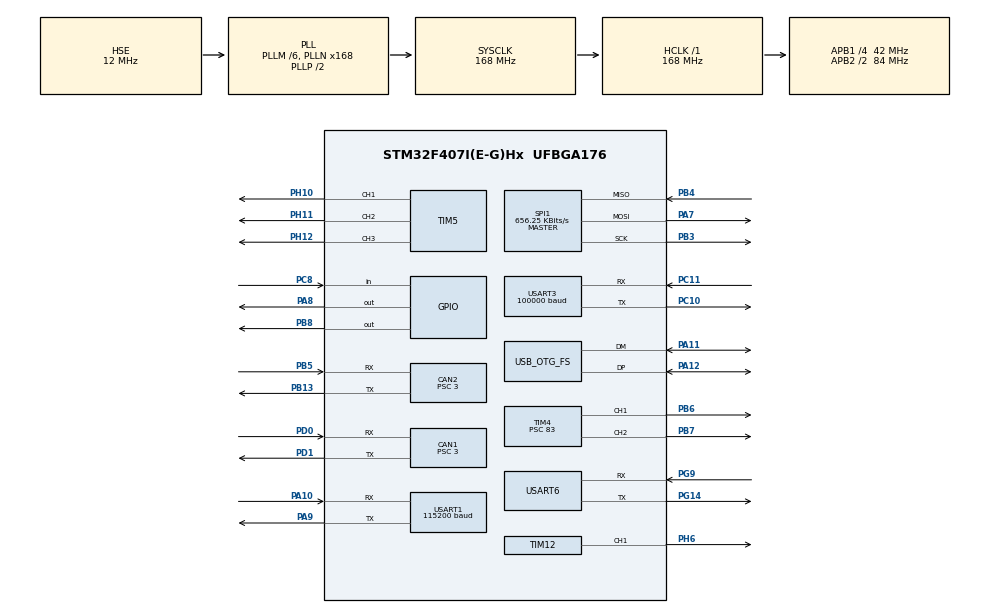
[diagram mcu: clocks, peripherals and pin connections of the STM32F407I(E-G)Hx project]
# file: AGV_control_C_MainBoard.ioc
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Mcu.Family=STM32F4
NVIC.USART3_IRQn=true\:5\:0\:false\:false\:true\:true\:true\:true
Dma.USART6_TX.3.MemInc=DMA_MINC_ENABLE
USB_DEVICE.CLASS_NAME_FS=CDC
PH0-OSC_IN.Signal=RCC_OSC_IN
Dma.USART3_RX.1.Mode=DMA_NORMAL
RCC.CortexFreq_Value=168000000
Dma.USART6_TX.3.PeriphInc=DMA_PINC_DISABLE
PH12.Signal=S_TIM5_CH3
NVIC.CAN2_RX0_IRQn=true\:5\:0\:false\:false\:true\:true\:true\:true
SPI1.VirtualType=VM_MASTER
PH10.Signal=S_TIM5_CH1
CAN1.AWUM=DISABLE
CAN2.CalculateTimeBit=999.99
USART1.BaudRate=115200
Dma.USART6_RX.2.Direction=DMA_PERIPH_TO_MEMORY
PC10.Signal=USART3_TX
SH.S_TIM5_CH2.0=TIM5_CH2,PWM Generation2 CH2
VP_RTC_VS_RTC_Activate.Mode=RTC_Enabled
PA11.Mode=Device_Only
Dma.SPI1_RX.4.PeriphInc=DMA_PINC_DISABLE
USB_DEVICE.VirtualMode-CDC_FS=Cdc
PB13.Signal=CAN2_TX
Dma.USART6_RX.2.MemDataAlignment=DMA_MDATAALIGN_BYTE
RCC.SYSCLKSource=RCC_SYSCLKSOURCE_PLLCLK
ProjectManager.StackSize=0x2000
VP_FREERTOS_VS_CMSIS_V2.Mode=CMSIS_V2
Dma.SPI1_TX.5.Instance=DMA2_Stream3
Dma.USART6_TX.3.PeriphDataAlignment=DMA_PDATAALIGN_BYTE
Dma.USART1_TX.0.Priority=DMA_PRIORITY_MEDIUM
PA12.Signal=USB_OTG_FS_DP
RTC.SynchPrediv=3199
Dma.USART3_RX.1.MemInc=DMA_MINC_ENABLE
USART3.BaudRate=100000
Dma.USART1_TX.0.Direction=DMA_MEMORY_TO_PERIPH
Dma.USART3_RX.1.Instance=DMA1_Stream1
Dma.USART6_TX.3.Priority=DMA_PRIORITY_MEDIUM
NVIC.CAN1_TX_IRQn=true\:5\:0\:false\:false\:true\:true\:true\:true
SPI1.Direction=SPI_DIRECTION_2LINES
RCC.HCLKFreq_Value=168000000
RCC.APB2TimFreq_Value=168000000
PB6.Signal=S_TIM4_CH1
Dma.USART3_RX.1.PeriphDataAlignment=DMA_PDATAALIGN_BYTE
SH.S_TIM5_CH3.0=TIM5_CH3,PWM Generation3 CH3
SPI1.CalculateBaudRate=656.25 KBits/s
Dma.USART6_RX.2.Instance=DMA2_Stream1
PD0.Signal=CAN1_RX
Dma.SPI1_RX.4.MemDataAlignment=DMA_MDATAALIGN_BYTE
RCC.AHBFreq_Value=168000000
PH0-OSC_IN.Mode=HSE-External-Oscillator
RCC.HSE_VALUE=12000000
PB3.Mode=Full_Duplex_Master
TIM12.Period=31111
PG14.Mode=Asynchronous
Dma.USART6_RX.2.Priority=DMA_PRIORITY_HIGH
PB4.Mode=Full_Duplex_Master
SH.S_TIM12_CH1.0=TIM12_CH1,PWM Generation1 CH1
Dma.USART3_RX.1.Priority=DMA_PRIORITY_HIGH
PA14.Mode=Serial_Wire
CAN2.Prescaler=3
PB5.Mode=CAN_Activate
RTC.AsynchPrediv=124
SH.S_TIM4_CH2.0=TIM4_CH2,PWM Generation2 CH2
PB7.Signal=S_TIM4_CH2
Dma.SPI1_TX.5.FIFOMode=DMA_FIFOMODE_DISABLE
PA8.Signal=GPIO_Output
VP_TIM12_VS_ClockSourceINT.Mode=Internal
Dma.SPI1_TX.5.Priority=DMA_PRIORITY_HIGH
TIM4.Period=19999
Dma.USART1_TX.0.PeriphDataAlignment=DMA_PDATAALIGN_BYTE
Dma.SPI1_RX.4.FIFOMode=DMA_FIFOMODE_DISABLE
PH1-OSC_OUT.Mode=HSE-External-Oscillator
Dma.SPI1_RX.4.MemInc=DMA_MINC_ENABLE
CAN1.Prescaler=3
Mcu.Package=UFBGA176
Dma.USART3_RX.1.FIFOMode=DMA_FIFOMODE_DISABLE
NVIC.DMA2_Stream7_IRQn=true\:5\:0\:false\:false\:true\:true\:false\:true
NVIC.TimeBase=TIM3_IRQn
CAN2.BS1=CAN_BS1_10TQ
CAN2.BS2=CAN_BS2_3TQ
USART6.VirtualMode=VM_ASYNC
Dma.USART3_RX.1.Direction=DMA_PERIPH_TO_MEMORY
NVIC.OTG_FS_IRQn=true\:5\:0\:false\:false\:true\:true\:false\:true
NVIC.TimeBaseIP=TIM3
PA10.Signal=USART1_RX
USB_OTG_FS.VirtualMode=Device_Only
Dma.USART1_TX.0.Instance=DMA2_Stream7
Dma.USART1_TX.0.FIFOMode=DMA_FIFOMODE_DISABLE
PC11.Mode=Asynchronous
RCC.APB2CLKDivider=RCC_HCLK_DIV2
Dma.SPI1_TX.5.Direction=DMA_MEMORY_TO_PERIPH
NVIC.DMA2_Stream2_IRQn=true\:5\:0\:false\:false\:true\:true\:false\:true
Dma.USART6_TX.3.MemDataAlignment=DMA_MDATAALIGN_BYTE
SH.S_TIM4_CH1.0=TIM4_CH1,PWM Generation1 CH1
Dma.Request2=USART6_RX
Dma.Request1=USART3_RX
RCC.APB1TimFreq_Value=84000000
Dma.Request4=SPI1_RX
Dma.Request3=USART6_TX
SH.S_TIM5_CH1.0=TIM5_CH1,PWM Generation1 CH1
Dma.Request5=SPI1_TX
PB13.Mode=CAN_Activate
NVIC.USART1_IRQn=true\:5\:0\:false\:false\:true\:true\:true\:true
Dma.Request0=USART1_TX
SPI1.BaudRatePrescaler=SPI_BAUDRATEPRESCALER_128
CAN1.CalculateTimeBit=999.99
PB4.Signal=SPI1_MISO
CAN1.CalculateTimeQuantum=71.42857142857143
Dma.SPI1_TX.5.MemInc=DMA_MINC_ENABLE
TIM4.Channel-PWM\ Generation1\ CH1=TIM_CHANNEL_1
CAN2.CalculateBaudRate=1000000
NVIC.CAN2_TX_IRQn=true\:5\:0\:false\:false\:true\:true\:true\:true
FREERTOS.Tasks01=ChassisTask,24,512,chassis_task,As weak,NULL,Dynamic,NULL,NULL;IMUTask,48,1024,INS_task1,As weak,NULL,Dynamic,NULL,NULL
Dma.USART1_TX.0.MemInc=DMA_MINC_ENABLE
PA7.Mode=Full_Duplex_Master
Dma.SPI1_TX.5.MemDataAlignment=DMA_MDATAALIGN_BYTE
Dma.USART1_TX.0.PeriphInc=DMA_PINC_DISABLE
PA10.Mode=Asynchronous
PH11.Signal=S_TIM5_CH2
USB_DEVICE.VirtualModeFS=Cdc_FS
PG9.Signal=USART6_RX
PC11.Signal=USART3_RX
CAN1.CalculateBaudRate=1000000
PC8.Signal=GPIO_Input
PG9.Mode=Asynchronous
PC10.Mode=Asynchronous
PD1.Signal=CAN1_TX
Dma.USART3_RX.1.MemDataAlignment=DMA_MDATAALIGN_BYTE
TIM5.Channel-PWM\ Generation3\ CH3=TIM_CHANNEL_3
NVIC.DMA1_Stream1_IRQn=true\:5\:0\:false\:false\:true\:true\:false\:true
NVIC.DMA2_Stream1_IRQn=true\:5\:0\:false\:false\:true\:false\:false\:true
RCC.APB1CLKDivider=RCC_HCLK_DIV4
Dma.SPI1_RX.4.Instance=DMA2_Stream2
Dma.USART6_TX.3.Mode=DMA_NORMAL
NVIC.USART6_IRQn=true\:5\:0\:false\:false\:true\:true\:true\:true
PA13.Signal=SYS_JTMS-SWDIO
Dma.SPI1_RX.4.Mode=DMA_NORMAL
PA9.Mode=Asynchronous
VP_SYS_VS_tim3.Mode=TIM3
CAN1.BS2=CAN_BS2_3TQ
CAN1.BS1=CAN_BS1_10TQ
ProjectManager.TargetToolchain=STM32CubeIDE
Dma.USART6_RX.2.MemInc=DMA_MINC_ENABLE
VP_USB_DEVICE_VS_USB_DEVICE_CDC_FS.Mode=CDC_FS
PA9.Signal=USART1_TX
Dma.SPI1_TX.5.Mode=DMA_NORMAL
Dma.USART6_RX.2.PeriphDataAlignment=DMA_PDATAALIGN_BYTE
NVIC.DMA2_Stream3_IRQn=true\:5\:0\:false\:false\:true\:true\:false\:true
NVIC.DMA2_Stream6_IRQn=true\:5\:0\:false\:false\:true\:true\:false\:true
TIM4.Prescaler=83
RCC.LSE_VALUE=32768
CAN1.ABOM=ENABLE
TIM12.Prescaler=1281
PG14.Signal=USART6_TX
Dma.USART6_TX.3.Direction=DMA_MEMORY_TO_PERIPH
Dma.USART1_TX.0.Mode=DMA_NORMAL
board=custom
RCC.VCOOutputFreq_Value=336000000
PD1.Mode=CAN_Activate
Dma.USART6_RX.2.FIFOMode=DMA_FIFOMODE_DISABLE
NVIC.TIM3_IRQn=true\:0\:0\:false\:false\:true\:false\:false\:true
Dma.USART6_RX.2.Mode=DMA_NORMAL
TIM12.Channel-PWM\ Generation1\ CH1=TIM_CHANNEL_1
TIM4.Channel-PWM\ Generation2\ CH2=TIM_CHANNEL_2
RCC.APB2Freq_Value=84000000
SPI1.Mode=SPI_MODE_MASTER
CAN2.CalculateTimeQuantum=71.42857142857143
PH1-OSC_OUT.Signal=RCC_OSC_OUT
CAN2.ABOM=ENABLE
PA13.Mode=Serial_Wire
Mcu.Name=STM32F407I(E-G)Hx
PD0.Mode=CAN_Activate
Dma.SPI1_RX.4.Priority=DMA_PRIORITY_VERY_HIGH
RCC.48MHZClocksFreq_Value=48000000
PB3.Signal=SPI1_SCK
TIM5.Channel-PWM\ Generation2\ CH2=TIM_CHANNEL_2
RCC.SYSCLKFreq_VALUE=168000000
PB5.Signal=CAN2_RX
Dma.SPI1_RX.4.Direction=DMA_PERIPH_TO_MEMORY
PA12.Mode=Device_Only
USART3.VirtualMode=VM_ASYNC
Dma.SPI1_TX.5.PeriphInc=DMA_PINC_DISABLE
USART1.VirtualMode=VM_ASYNC
PA11.Signal=USB_OTG_FS_DM
Dma.USART1_TX.0.MemDataAlignment=DMA_MDATAALIGN_BYTE
TIM5.Channel-PWM\ Generation1\ CH1=TIM_CHANNEL_1
PA14.Signal=SYS_JTCK-SWCLK
ProjectManager.HeapSize=0x2000
PH6.Signal=S_TIM12_CH1
Dma.USART6_TX.3.FIFOMode=DMA_FIFOMODE_DISABLE
Dma.USART6_TX.3.Instance=DMA2_Stream6
RCC.HSI_VALUE=16000000
VP_TIM4_VS_ClockSourceINT.Mode=Internal
RCC.PLLQ=7
NVIC.PriorityGroup=NVIC_PRIORITYGROUP_4
RCC.PLLM=6
Dma.SPI1_TX.5.PeriphDataAlignment=DMA_PDATAALIGN_BYTE
RCC.PLLN=168
PB8.Signal=GPIO_Output
Dma.USART6_RX.2.PeriphInc=DMA_PINC_DISABLE
RCC.APB1Freq_Value=42000000
NVIC.CAN1_RX0_IRQn=true\:5\:0\:false\:false\:true\:true\:true\:true
Dma.USART3_RX.1.PeriphInc=DMA_PINC_DISABLE
Dma.SPI1_RX.4.PeriphDataAlignment=DMA_PDATAALIGN_BYTE
PA7.Signal=SPI1_MOSI

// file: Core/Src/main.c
/* USER CODE BEGIN Header */
/**
  ******************************************************************************
  * @file           : main.c
  * @brief          : Main program body
  ******************************************************************************
  * @attention
  *
  * <h2><center>&copy; Copyright (c) 2021 STMicroelectronics.
  * All rights reserved.</center></h2>
  *
  * This software component is licensed by ST under Ultimate Liberty license
  * SLA0044, the "License"; You may not use this file except in compliance with
  * the License. You may obtain a copy of the License at:
  *                             www.st.com/SLA0044
  *
  ******************************************************************************
  */
/* USER CODE END Header */
#include "main.h"
#include "cmsis_os.h"
#include "can.h"
#include "dma.h"
#include "rtc.h"
#include "spi.h"
#include "tim.h"
#include "usart.h"
#include "usb_device.h"
#include "gpio.h"

/* USER CODE BEGIN Includes */
#include "bsp_can.h"
#include "remote_control.h"
#include "chassis_task.h"
#include "INS_task.h"
/* USER CODE END Includes */

void SystemClock_Config(void);
void MX_FREERTOS_Init(void);

int main(void)
{

  /* MCU Configuration--------------------------------------------------------*/

  /* Reset of all peripherals, Initializes the Flash interface and the Systick. */
  HAL_Init();

  /* Configure the system clock */
  SystemClock_Config();

  /* Initialize all configured peripherals */
  MX_GPIO_Init();
  MX_DMA_Init();
  MX_CAN1_Init();
  MX_CAN2_Init();
  MX_RTC_Init();
  MX_TIM4_Init();
  MX_TIM5_Init();
  MX_TIM12_Init();
  MX_USART1_UART_Init();
  MX_USART3_UART_Init();
  MX_SPI1_Init();
  MX_USART6_UART_Init();
  /* USER CODE BEGIN 2 */
  BSP_CAN_Filtering_Init();
  remote_control_init();
  /* USER CODE END 2 */

  /* Init scheduler */
  osKernelInitialize();  /* Call init function for freertos objects (in freertos.c) */
  MX_FREERTOS_Init();
  /* Start scheduler */
  osKernelStart();

  /* We should never get here as control is now taken by the scheduler */
  /* Infinite loop */
  while (1)
  {

  }
}

void SystemClock_Config(void)
{
  RCC_OscInitTypeDef RCC_OscInitStruct = {0};
  RCC_ClkInitTypeDef RCC_ClkInitStruct = {0};
  RCC_PeriphCLKInitTypeDef PeriphClkInitStruct = {0};

  /** Configure the main internal regulator output voltage
  */
  __HAL_RCC_PWR_CLK_ENABLE();
  __HAL_PWR_VOLTAGESCALING_CONFIG(PWR_REGULATOR_VOLTAGE_SCALE1);
  /** Initializes the RCC Oscillators according to the specified parameters
  * in the RCC_OscInitTypeDef structure.
  */
  RCC_OscInitStruct.OscillatorType = RCC_OSCILLATORTYPE_LSI|RCC_OSCILLATORTYPE_HSE;
  RCC_OscInitStruct.HSEState = RCC_HSE_ON;
  RCC_OscInitStruct.LSIState = RCC_LSI_ON;
  RCC_OscInitStruct.PLL.PLLState = RCC_PLL_ON;
  RCC_OscInitStruct.PLL.PLLSource = RCC_PLLSOURCE_HSE;
  RCC_OscInitStruct.PLL.PLLM = 6;
  RCC_OscInitStruct.PLL.PLLN = 168;
  RCC_OscInitStruct.PLL.PLLP = RCC_PLLP_DIV2;
  RCC_OscInitStruct.PLL.PLLQ = 7;
  if (HAL_RCC_OscConfig(&RCC_OscInitStruct) != HAL_OK)
  {
    Error_Handler();
  }
  /** Initializes the CPU, AHB and APB buses clocks
  */
  RCC_ClkInitStruct.ClockType = RCC_CLOCKTYPE_HCLK|RCC_CLOCKTYPE_SYSCLK
                              |RCC_CLOCKTYPE_PCLK1|RCC_CLOCKTYPE_PCLK2;
  RCC_ClkInitStruct.SYSCLKSource = RCC_SYSCLKSOURCE_PLLCLK;
  RCC_ClkInitStruct.AHBCLKDivider = RCC_SYSCLK_DIV1;
  RCC_ClkInitStruct.APB1CLKDivider = RCC_HCLK_DIV4;
  RCC_ClkInitStruct.APB2CLKDivider = RCC_HCLK_DIV2;

  if (HAL_RCC_ClockConfig(&RCC_ClkInitStruct, FLASH_LATENCY_5) != HAL_OK)
  {
    Error_Handler();
  }
  PeriphClkInitStruct.PeriphClockSelection = RCC_PERIPHCLK_RTC;
  PeriphClkInitStruct.RTCClockSelection = RCC_RTCCLKSOURCE_LSI;
  if (HAL_RCCEx_PeriphCLKConfig(&PeriphClkInitStruct) != HAL_OK)
  {
    Error_Handler();
  }
}

 /**
  * @brief  Period elapsed callback in non blocking mode
  * @note   This function is called  when TIM3 interrupt took place, inside
  * HAL_TIM_IRQHandler(). It makes a direct call to HAL_IncTick() to increment
  * a global variable "uwTick" used as application time base.
  * @param  htim : TIM handle
  * @retval None
  */
void HAL_TIM_PeriodElapsedCallback(TIM_HandleTypeDef *htim)
{
  if (htim->Instance == TIM3) {
    HAL_IncTick();
  }
}

void Error_Handler(void)
{
  __disable_irq();
  while (1)
  {
  }
}

/************************ (C) COPYRIGHT STMicroelectronics *****END OF FILE****/

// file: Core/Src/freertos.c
/* USER CODE BEGIN Header */
/**
  ******************************************************************************
  * File Name          : freertos.c
  * Description        : Code for freertos applications
  ******************************************************************************
  * @attention
  *
  * <h2><center>&copy; Copyright (c) 2021 STMicroelectronics.
  * All rights reserved.</center></h2>
  *
  * This software component is licensed by ST under Ultimate Liberty license
  * SLA0044, the "License"; You may not use this file except in compliance with
  * the License. You may obtain a copy of the License at:
  *                             www.st.com/SLA0044
  *
  ******************************************************************************
  */
/* USER CODE END Header */

#include "FreeRTOS.h"
#include "task.h"
#include "main.h"
#include "cmsis_os.h"

/* Definitions for ChassisTask */
osThreadId_t ChassisTaskHandle;
const osThreadAttr_t ChassisTask_attributes = {
  .name = "ChassisTask",
  .stack_size = 512 * 4,
  .priority = (osPriority_t) osPriorityNormal,
};
/* Definitions for IMUTask */
osThreadId_t IMUTaskHandle;
const osThreadAttr_t IMUTask_attributes = {
  .name = "IMUTask",
  .stack_size = 1024 * 4,
  .priority = (osPriority_t) osPriorityRealtime,
};

void chassis_task(void *argument);
void INS_task1(void *argument);

extern void MX_USB_DEVICE_Init(void);
void MX_FREERTOS_Init(void); /* (MISRA C 2004 rule 8.1) */

void MX_FREERTOS_Init(void) {

  /* Create the thread(s) */
  /* creation of ChassisTask */
  ChassisTaskHandle = osThreadNew(chassis_task, NULL, &ChassisTask_attributes);

  /* creation of IMUTask */
  IMUTaskHandle = osThreadNew(INS_task1, NULL, &IMUTask_attributes);

}

__weak void chassis_task(void *argument)
{
  /* init code for USB_DEVICE */
  MX_USB_DEVICE_Init();
  for(;;)
  {
    osDelay(1);
  }
}

__weak void INS_task1(void *argument)
{
  for(;;)
  {
    osDelay(1);
  }
}

/************************ (C) COPYRIGHT STMicroelectronics *****END OF FILE****/
